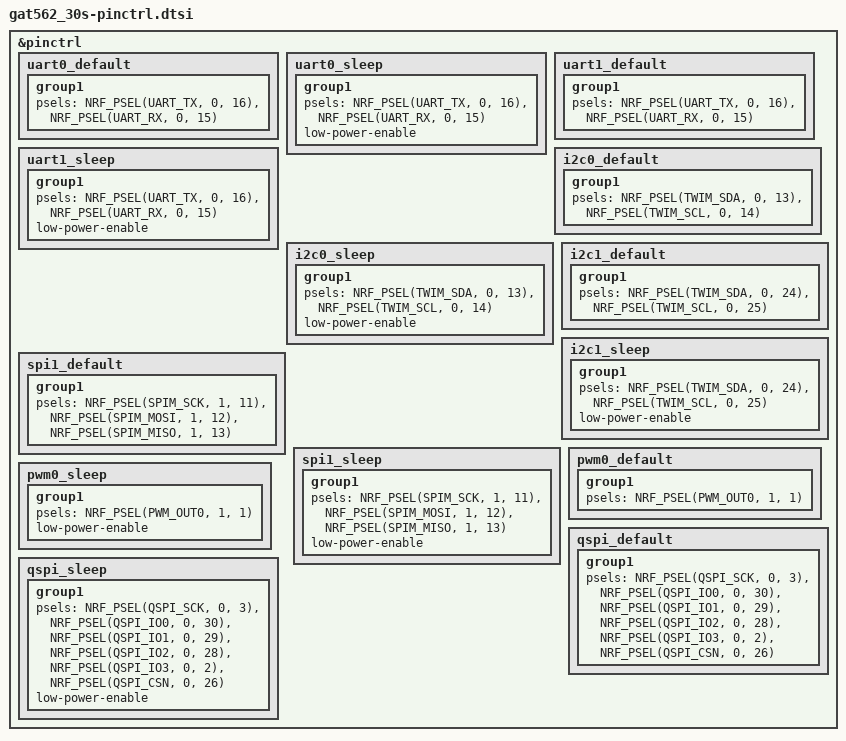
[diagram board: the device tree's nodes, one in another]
/*
 * SPDX-License-Identifier: Apache-2.0
 * GAT562 30S Mesh Kit pin control.
 *
 * RAK4631 core-module pinout (UART/I2C/SPI/QSPI identical to upstream
 * rak4631) plus a PWM channel for the onboard buzzer on P1.01.
 */

&pinctrl {
	/* GPS on UART0: MCU TX P0.16 -> GPS RX, MCU RX P0.15 <- GPS TX.
	 * The GPS is wired to P0.15/P0.16; it runs on UARTE0 because UARTE1's
	 * interrupt-driven RX did not feed the modem backend on this SoC (the
	 * other nRF52 GPS boards in this tree also use uart0 + gnss-nmea-generic). */
	uart0_default: uart0_default {
		group1 {
			psels = <NRF_PSEL(UART_TX, 0, 16)>,
				<NRF_PSEL(UART_RX, 0, 15)>;
		};
	};

	uart0_sleep: uart0_sleep {
		group1 {
			psels = <NRF_PSEL(UART_TX, 0, 16)>,
				<NRF_PSEL(UART_RX, 0, 15)>;
			low-power-enable;
		};
	};

	/* GPS on UART1: MCU TX P0.16 -> GPS RX, MCU RX P0.15 <- GPS TX */
	uart1_default: uart1_default {
		group1 {
			psels = <NRF_PSEL(UART_TX, 0, 16)>,
				<NRF_PSEL(UART_RX, 0, 15)>;
		};
	};

	uart1_sleep: uart1_sleep {
		group1 {
			psels = <NRF_PSEL(UART_TX, 0, 16)>,
				<NRF_PSEL(UART_RX, 0, 15)>;
			low-power-enable;
		};
	};

	/* I2C0: SSD1306 OLED + sensors (SDA P0.13 / SCL P0.14) */
	i2c0_default: i2c0_default {
		group1 {
			psels = <NRF_PSEL(TWIM_SDA, 0, 13)>,
				<NRF_PSEL(TWIM_SCL, 0, 14)>;
		};
	};

	i2c0_sleep: i2c0_sleep {
		group1 {
			psels = <NRF_PSEL(TWIM_SDA, 0, 13)>,
				<NRF_PSEL(TWIM_SCL, 0, 14)>;
			low-power-enable;
		};
	};

	/* I2C1 (P0.24/P0.25) — defined for parity, not enabled */
	i2c1_default: i2c1_default {
		group1 {
			psels = <NRF_PSEL(TWIM_SDA, 0, 24)>,
				<NRF_PSEL(TWIM_SCL, 0, 25)>;
		};
	};

	i2c1_sleep: i2c1_sleep {
		group1 {
			psels = <NRF_PSEL(TWIM_SDA, 0, 24)>,
				<NRF_PSEL(TWIM_SCL, 0, 25)>;
			low-power-enable;
		};
	};

	/* LoRa SX1262 on SPI1: SCK P1.11 / MOSI P1.12 / MISO P1.13 */
	spi1_default: spi1_default {
		group1 {
			psels = <NRF_PSEL(SPIM_SCK, 1, 11)>,
				<NRF_PSEL(SPIM_MOSI, 1, 12)>,
				<NRF_PSEL(SPIM_MISO, 1, 13)>;
		};
	};

	spi1_sleep: spi1_sleep {
		group1 {
			psels = <NRF_PSEL(SPIM_SCK, 1, 11)>,
				<NRF_PSEL(SPIM_MOSI, 1, 12)>,
				<NRF_PSEL(SPIM_MISO, 1, 13)>;
			low-power-enable;
		};
	};

	/* Buzzer on PWM0 -> P1.01 */
	pwm0_default: pwm0_default {
		group1 {
			psels = <NRF_PSEL(PWM_OUT0, 1, 1)>;
		};
	};

	pwm0_sleep: pwm0_sleep {
		group1 {
			psels = <NRF_PSEL(PWM_OUT0, 1, 1)>;
			low-power-enable;
		};
	};

	/* QSPI pins (kept for parity; &qspi is disabled on this board) */
	qspi_default: qspi_default {
		group1 {
			psels = <NRF_PSEL(QSPI_SCK, 0, 3)>,
				<NRF_PSEL(QSPI_IO0, 0, 30)>,
				<NRF_PSEL(QSPI_IO1, 0, 29)>,
				<NRF_PSEL(QSPI_IO2, 0, 28)>,
				<NRF_PSEL(QSPI_IO3, 0, 2)>,
				<NRF_PSEL(QSPI_CSN, 0, 26)>;
		};
	};

	qspi_sleep: qspi_sleep {
		group1 {
			psels = <NRF_PSEL(QSPI_SCK, 0, 3)>,
				<NRF_PSEL(QSPI_IO0, 0, 30)>,
				<NRF_PSEL(QSPI_IO1, 0, 29)>,
				<NRF_PSEL(QSPI_IO2, 0, 28)>,
				<NRF_PSEL(QSPI_IO3, 0, 2)>,
				<NRF_PSEL(QSPI_CSN, 0, 26)>;
			low-power-enable;
		};
	};
};
